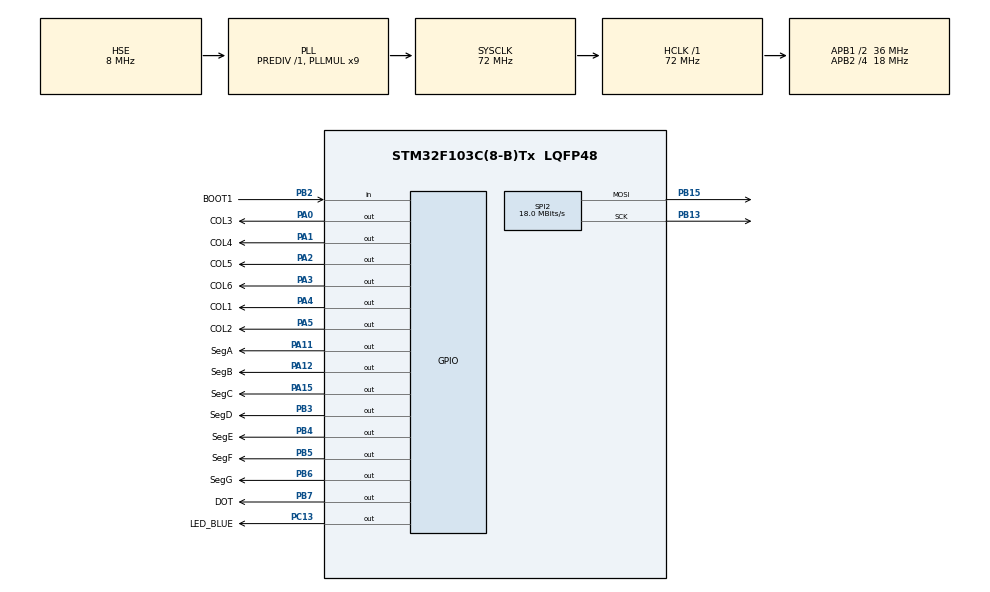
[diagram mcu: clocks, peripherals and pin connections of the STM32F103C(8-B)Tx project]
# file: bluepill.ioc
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ADC1.Channel-2\#ChannelRegularConversion=ADC_CHANNEL_TEMPSENSOR
ADC1.ExternalTrigConv=ADC_EXTERNALTRIGCONV_T3_TRGO
ADC1.NbrOfConversionFlag=1
ADC1.Rank-2\#ChannelRegularConversion=1
ADC1.SamplingTime-2\#ChannelRegularConversion=ADC_SAMPLETIME_1CYCLE_5
ADC1.master=1
Dma.ADC1.0.Direction=DMA_PERIPH_TO_MEMORY
Dma.ADC1.0.Instance=DMA1_Channel1
Dma.ADC1.0.MemDataAlignment=DMA_MDATAALIGN_HALFWORD
Dma.ADC1.0.MemInc=DMA_MINC_ENABLE
Dma.ADC1.0.Mode=DMA_NORMAL
Dma.ADC1.0.PeriphDataAlignment=DMA_PDATAALIGN_HALFWORD
Dma.ADC1.0.PeriphInc=DMA_PINC_DISABLE
Dma.ADC1.0.Priority=DMA_PRIORITY_LOW
Dma.Request0=ADC1
Mcu.Family=STM32F1
Mcu.Name=STM32F103C(8-B)Tx
Mcu.Package=LQFP48
NVIC.ADC1_2_IRQn=true\:0\:0\:false\:false\:true\:true\:true
NVIC.DMA1_Channel1_IRQn=true\:0\:0\:false\:false\:true\:true\:true
NVIC.PriorityGroup=NVIC_PRIORITYGROUP_4
PA0-WKUP.GPIO_Label=COL3
PA0-WKUP.Signal=GPIO_Output
PA1.GPIO_Label=COL4
PA1.Signal=GPIO_Output
PA11.GPIO_Label=SegA
PA11.Signal=GPIO_Output
PA12.GPIO_Label=SegB
PA12.Signal=GPIO_Output
PA13.Mode=Serial_Wire
PA13.Signal=SYS_JTMS-SWDIO
PA14.Mode=Serial_Wire
PA14.Signal=SYS_JTCK-SWCLK
PA15.GPIO_Label=SegC
PA15.Signal=GPIO_Output
PA2.GPIO_Label=COL5
PA2.Signal=GPIO_Output
PA3.GPIO_Label=COL6
PA3.Signal=GPIO_Output
PA4.GPIO_Label=COL1
PA4.Signal=GPIO_Output
PA5.GPIO_Label=COL2
PA5.Signal=GPIO_Output
PB13.Mode=TX_Only_Simplex_Unidirect_Master
PB13.Signal=SPI2_SCK
PB15.Mode=TX_Only_Simplex_Unidirect_Master
PB15.Signal=SPI2_MOSI
PB2.GPIO_Label=BOOT1
PB2.Signal=GPIO_Input
PB3.GPIO_Label=SegD
PB3.Signal=GPIO_Output
PB4.GPIO_Label=SegE
PB4.Signal=GPIO_Output
PB5.GPIO_Label=SegF
PB5.Signal=GPIO_Output
PB6.GPIO_Label=SegG
PB6.Signal=GPIO_Output
PB7.GPIO_Label=DOT
PB7.Signal=GPIO_Output
PC13-TAMPER-RTC.GPIO_Label=LED_BLUE
PC13-TAMPER-RTC.GPIO_ModeDefaultOutputPP=GPIO_MODE_OUTPUT_OD
PC13-TAMPER-RTC.Signal=GPIO_Output
PD0-OSC_IN.Mode=HSE-External-Oscillator
PD0-OSC_IN.Signal=RCC_OSC_IN
PD1-OSC_OUT.Mode=HSE-External-Oscillator
PD1-OSC_OUT.Signal=RCC_OSC_OUT
ProjectManager.HeapSize=0x200
ProjectManager.StackSize=0x200
ProjectManager.TargetToolchain=STM32CubeIDE
RCC.AHBFreq_Value=72000000
RCC.APB1CLKDivider=RCC_HCLK_DIV2
RCC.APB1Freq_Value=36000000
RCC.APB1TimFreq_Value=72000000
RCC.APB2CLKDivider=RCC_HCLK_DIV4
RCC.APB2Freq_Value=18000000
RCC.APB2TimFreq_Value=36000000
RCC.HCLKFreq_Value=72000000
RCC.PLLMUL=RCC_PLL_MUL9
RCC.PLLSourceVirtual=RCC_PLLSOURCE_HSE
RCC.SYSCLKFreq_VALUE=72000000
RCC.SYSCLKSource=RCC_SYSCLKSOURCE_PLLCLK
RCC.USBFreq_Value=72000000
SPI2.CRCCalculation=SPI_CRCCALCULATION_DISABLE
SPI2.CalculateBaudRate=18.0 MBits/s
SPI2.Direction=SPI_DIRECTION_2LINES
SPI2.Mode=SPI_MODE_MASTER
SPI2.VirtualType=VM_MASTER
TIM3.ClockDivision=TIM_CLOCKDIVISION_DIV1
TIM3.Period=19999
TIM3.TIM_MasterOutputTrigger=TIM_TRGO_UPDATE
VP_ADC1_TempSens_Input.Mode=IN-TempSens
VP_TIM3_VS_ClockSourceINT.Mode=Internal
board=custom

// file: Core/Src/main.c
/* USER CODE BEGIN Header */
/**
 ******************************************************************************
 * @file           : main.c
 * @brief          : Main program body
 ******************************************************************************
 * @attention
 *
 * <h2><center>&copy; Copyright (c) 2021 STMicroelectronics.
 * All rights reserved.</center></h2>
 *
 * This software component is licensed by ST under BSD 3-Clause license,
 * the "License"; You may not use this file except in compliance with the
 * License. You may obtain a copy of the License at:
 *                        opensource.org/licenses/BSD-3-Clause
 *
 ******************************************************************************
 */
/* USER CODE END Header */
#include "main.h"
#include "adc.h"
#include "dma.h"
#include "gpio.h"
#include "spi.h"
#include "tim.h"

void SystemClock_Config(void);
/* USER CODE BEGIN PFP */
void RealMain(void);
/* USER CODE END PFP */

int main(void)
{

    /* MCU Configuration--------------------------------------------------------*/

    /* Reset of all peripherals, Initializes the Flash interface and the Systick. */
    HAL_Init();

    /* Configure the system clock */
    SystemClock_Config();

    /* Initialize all configured peripherals */
    MX_GPIO_Init();
    MX_DMA_Init();
    MX_ADC1_Init();
    MX_TIM3_Init();
    MX_SPI2_Init();
    /* USER CODE BEGIN 2 */
    RealMain();
    /* USER CODE END 2 */

    /* Infinite loop */
    while (1)
    {

    }
}

void SystemClock_Config(void)
{
    RCC_OscInitTypeDef RCC_OscInitStruct = {0};
    RCC_ClkInitTypeDef RCC_ClkInitStruct = {0};
    RCC_PeriphCLKInitTypeDef PeriphClkInit = {0};

    /** Initializes the RCC Oscillators according to the specified parameters
     * in the RCC_OscInitTypeDef structure.
     */
    RCC_OscInitStruct.OscillatorType = RCC_OSCILLATORTYPE_HSE;
    RCC_OscInitStruct.HSEState = RCC_HSE_ON;
    RCC_OscInitStruct.HSEPredivValue = RCC_HSE_PREDIV_DIV1;
    RCC_OscInitStruct.HSIState = RCC_HSI_ON;
    RCC_OscInitStruct.PLL.PLLState = RCC_PLL_ON;
    RCC_OscInitStruct.PLL.PLLSource = RCC_PLLSOURCE_HSE;
    RCC_OscInitStruct.PLL.PLLMUL = RCC_PLL_MUL9;
    if (HAL_RCC_OscConfig(&RCC_OscInitStruct) != HAL_OK)
    {
        Error_Handler();
    }
    /** Initializes the CPU, AHB and APB buses clocks
     */
    RCC_ClkInitStruct.ClockType = RCC_CLOCKTYPE_HCLK | RCC_CLOCKTYPE_SYSCLK | RCC_CLOCKTYPE_PCLK1 | RCC_CLOCKTYPE_PCLK2;
    RCC_ClkInitStruct.SYSCLKSource = RCC_SYSCLKSOURCE_PLLCLK;
    RCC_ClkInitStruct.AHBCLKDivider = RCC_SYSCLK_DIV1;
    RCC_ClkInitStruct.APB1CLKDivider = RCC_HCLK_DIV2;
    RCC_ClkInitStruct.APB2CLKDivider = RCC_HCLK_DIV4;

    if (HAL_RCC_ClockConfig(&RCC_ClkInitStruct, FLASH_LATENCY_2) != HAL_OK)
    {
        Error_Handler();
    }
    PeriphClkInit.PeriphClockSelection = RCC_PERIPHCLK_ADC;
    PeriphClkInit.AdcClockSelection = RCC_ADCPCLK2_DIV2;
    if (HAL_RCCEx_PeriphCLKConfig(&PeriphClkInit) != HAL_OK)
    {
        Error_Handler();
    }
}

void Error_Handler(void)
{
    /* USER CODE BEGIN Error_Handler_Debug */
    /* User can add his own implementation to report the HAL error return state */
    __disable_irq();
    while (1)
    {}
    /* USER CODE END Error_Handler_Debug */
}

/************************ (C) COPYRIGHT STMicroelectronics *****END OF FILE****/
